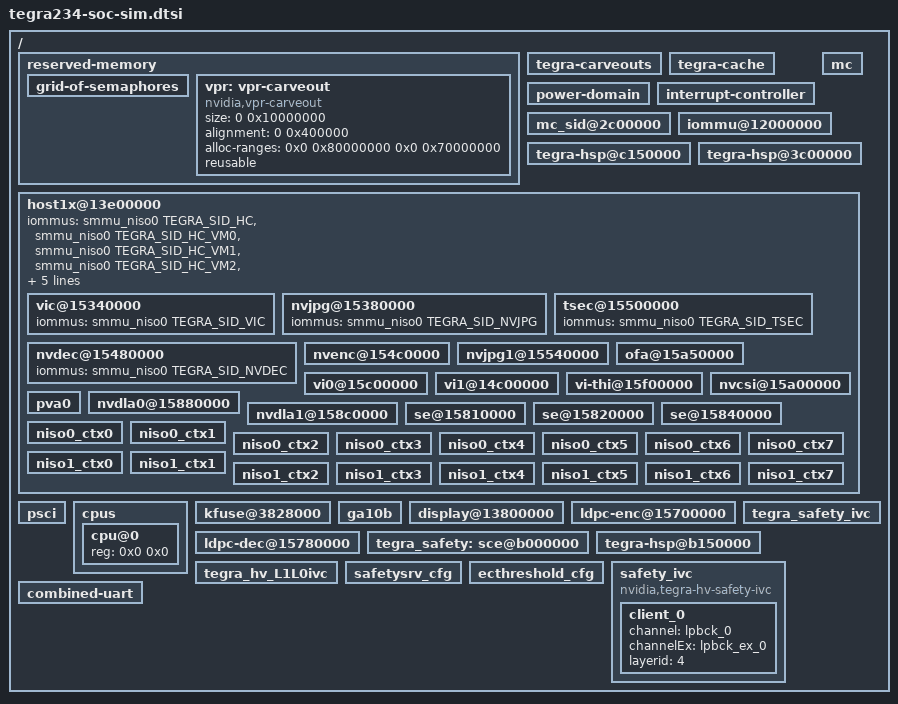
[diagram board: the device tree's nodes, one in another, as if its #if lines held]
/*
 * Copyright (c) 2017-2020, NVIDIA CORPORATION.  All rights reserved.
 *
 * This program is free software; you can redistribute it and/or modify it
 * under the terms and conditions of the GNU General Public License,
 * version 2, as published by the Free Software Foundation.
 *
 * This program is distributed in the hope it will be useful, but WITHOUT
 * ANY WARRANTY; without even the implied warranty of MERCHANTABILITY or
 * FITNESS FOR A PARTICULAR PURPOSE.  See the GNU General Public License for
 * more details.
 *
 * You should have received a copy of the GNU General Public License
 * along with this program.  If not, see <http://www.gnu.org/licenses/>.
 */

/*
 * tegra234-soc-sim.dtsi: Simulation and Emulation SOC base
 *			  DTSI file used for all sim DTSI.
 */

#include <tegra234-soc/tegra234-soc-base.dtsi>

/ {
	reserved-memory {
		grid-of-semaphores {
			status = "okay";
		};

		vpr: vpr-carveout {
				compatible = "nvidia,vpr-carveout";
				size = <0 0x10000000>;
				alignment = <0 0x400000>;
				alloc-ranges = <0x0 0x80000000 0x0 0x70000000>;
				reusable;
		};
	};

	tegra-carveouts {
		status = "okay";
	};

	/* L4 cache */
	tegra-cache {
		status = "okay";
	};

	power-domain {
		status = "okay";
	};

	interrupt-controller {
		status = "okay";
	};

	mc {
		status = "okay";
	};

	mc_sid@2c00000 {
		status = "okay";
	};

	iommu@12000000 {
		status = "okay";
	};

	tegra-hsp@c150000 {
		status = "okay";
	};

	tegra-hsp@3c00000 {
		status = "okay";
	};

	host1x@13e00000 {
#if TEGRA_IOMMU_DT_VERSION >= DT_VERSION_2
		iommus = <&smmu_niso0 TEGRA_SID_HC>,
			 <&smmu_niso0 TEGRA_SID_HC_VM0>,
			 <&smmu_niso0 TEGRA_SID_HC_VM1>,
			 <&smmu_niso0 TEGRA_SID_HC_VM2>,
			 <&smmu_niso0 TEGRA_SID_HC_VM3>,
			 <&smmu_niso0 TEGRA_SID_HC_VM4>,
			 <&smmu_niso0 TEGRA_SID_HC_VM5>,
			 <&smmu_niso0 TEGRA_SID_HC_VM6>,
			 <&smmu_niso0 TEGRA_SID_HC_VM7>;

		vic@15340000 {
			iommus = <&smmu_niso0 TEGRA_SID_VIC>;
			status = "okay";
		};

		nvjpg@15380000 {
			iommus = <&smmu_niso0 TEGRA_SID_NVJPG>;
			status = "okay";
		};

		tsec@15500000 {
			iommus = <&smmu_niso0 TEGRA_SID_TSEC>;
			status = "okay";
		};

		nvdec@15480000 {
			iommus = <&smmu_niso0 TEGRA_SID_NVDEC>;
			status = "okay";
		};
#else
		vic@15340000 {
			status = "okay";
		};

		nvjpg@15380000 {
			status = "okay";
		};

		tsec@15500000 {
			status = "okay";
		};

		nvdec@15480000 {
			status = "okay";
		};
#endif
		nvenc@154c0000 {
			status = "okay";
		};

		nvjpg1@15540000 {
			status = "okay";
		};

		ofa@15a50000 {
			status = "okay";
		};

		vi0@15c00000 {
			status = "okay";
		};

		vi1@14c00000 {
			status = "okay";
		};

		vi-thi@15f00000 {
			status = "okay";
		};

		nvcsi@15a00000 {
			status = "okay";
		};

		pva0 {
			status = "okay";
		};

		nvdla0@15880000 {
			status = "okay";
		};

		nvdla1@158c0000 {
			status = "okay";
		};

		se@15810000 {
			status = "okay";
		};

		se@15820000 {
			status = "okay";
		};

		se@15840000 {
			status = "okay";
		};

		niso0_ctx0 {
			status = "okay";
		};

		niso0_ctx1 {
			status = "okay";
		};

		niso0_ctx2 {
			status = "okay";
		};

		niso0_ctx3 {
			status = "okay";
		};

		niso0_ctx4 {
			status = "okay";
		};

		niso0_ctx5 {
			status = "okay";
		};

		niso0_ctx6 {
			status = "okay";
		};

		niso0_ctx7 {
			status = "okay";
		};

#if TEGRA_IOMMU_DT_VERSION >= DT_VERSION_2
		niso1_ctx0 {
			status = "okay";
		};

		niso1_ctx1 {
			status = "okay";
		};

		niso1_ctx2 {
			status = "okay";
		};

		niso1_ctx3 {
			status = "okay";
		};

		niso1_ctx4 {
			status = "okay";
		};

		niso1_ctx5 {
			status = "okay";
		};

		niso1_ctx6 {
			status = "okay";
		};

		niso1_ctx7 {
			status = "okay";
		};
#endif
	};

	psci {
		status = "okay";
	};

	cpus {
		/*
		 * Override the MPIDR value for simulator because MPIDR
		 * value returned by the CPU on simulator is different
		 * from the one in soc-base dtsi.
		 */
		cpu@0 {
			reg = <0x0 0x0>;
		};
	};

	kfuse@3828000 {
		status = "okay";
	};

	ga10b {
		status = "okay";
	};

	mc {
		/delete-property/ ranges;
		/delete-node/ mssnvlink@1f20000;
	};

	display@13800000 {
		status = "okay";
	};

	ldpc-enc@15700000 {
                status = "okay";
        };

        ldpc-dec@15780000 {
                status = "okay";
        };

	tegra_safety: sce@b000000 {
		status = "okay";
	};

	tegra_safety_ivc: tegra_safety_ivc {
                status = "okay";
        };

	tegra-hsp@b150000 {
		status = "okay";
	};

	tegra_hv_L1L0ivc {
		status = "okay";
	};

	safetysrv_cfg{
		status = "okay";
        };

        ecthreshold_cfg: ecthreshold_cfg {
		status="okay";
	};

        safety_ivc {
		compatible = "nvidia,tegra-hv-safety-ivc";
		client_0 {
			channel = "lpbck_0";
			channelEx = "lpbck_ex_0";
			layerid = <4>;
		};
	};

	combined-uart {
		status = "okay";
	};
};
